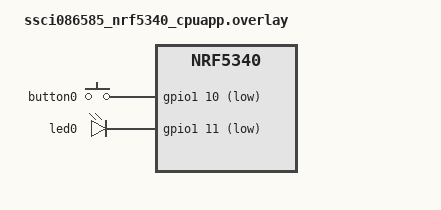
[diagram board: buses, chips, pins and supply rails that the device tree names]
/* Configure button and LED for Serial Recovery */
/ {
	aliases {
		mcuboot-button0 = &button0;
		mcuboot-led0 = &led0;
	};

	chosen {
		zephyr,code-partition = &boot_partition;
	};
};

&button0 {
	gpios = <&gpio1 10 GPIO_ACTIVE_LOW>;
};

&led0 {
	gpios = <&gpio1 11 GPIO_ACTIVE_LOW>;
};

// &uart0_default {
// 	group1 {
// 		psels = <NRF_PSEL(UART_TX, 0, 13)>,
// 				<NRF_PSEL(UART_RX, 0, 15)>;
// 	};
// };

// &uart0_sleep {
// 	group1 {
// 		psels = <NRF_PSEL(UART_TX, 0, 13)>,
// 				<NRF_PSEL(UART_RX, 0, 15)>;
// 		low-power-enable;
// 	};
// };
